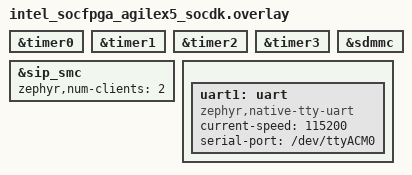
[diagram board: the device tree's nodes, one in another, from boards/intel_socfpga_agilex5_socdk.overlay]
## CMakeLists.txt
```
# SPDX-License-Identifier: Apache-2.0

cmake_minimum_required(VERSION 3.20.0)
find_package(Zephyr REQUIRED HINTS $ENV{ZEPHYR_BASE})
project(shell_module)

target_sources(app PRIVATE src/main.c mylib/test_module.c)
target_sources_ifdef(CONFIG_SHELL_DYNAMIC_CMDS app PRIVATE mylib/dynamic_cmd.c)
target_sources_ifdef(CONFIG_SHELL_BACKEND_SERIAL app PRIVATE mylib/uart_reinit.c)
target_sources_ifdef(CONFIG_SHELL_BACKEND_SERIAL app PRIVATE include/ahu_led.h)
target_sources_ifdef(CONFIG_SHELL_BACKEND_SERIAL app PRIVATE include/ahu_shell.h)
target_sources_ifdef(CONFIG_SHELL_BACKEND_SERIAL app PRIVATE include/ahu_timer.h)
target_sources_ifdef(CONFIG_SHELL_BACKEND_SERIAL app PRIVATE include/ahu_uart.h)
target_sources_ifdef(CONFIG_SHELL_BACKEND_SERIAL app PRIVATE include/hci.h)
target_sources_ifdef(CONFIG_SHELL_BACKEND_SERIAL app PRIVATE include/ble_central.h)
target_sources_ifdef(CONFIG_SHELL_BACKEND_SERIAL app PRIVATE include/ble_devices.h)
target_sources_ifdef(CONFIG_SHELL_BACKEND_SERIAL app PRIVATE include/ble_rules.h)
target_sources_ifdef(CONFIG_SHELL_BACKEND_SERIAL app PRIVATE ../Thingy52/include/ble_defs.h)
```

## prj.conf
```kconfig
CONFIG_PRINTK=y
CONFIG_SHELL=y
CONFIG_LOG=y
CONFIG_LOG_CMDS=y
CONFIG_INIT_STACKS=y
CONFIG_THREAD_STACK_INFO=y
CONFIG_KERNEL_SHELL=y
CONFIG_THREAD_MONITOR=y
CONFIG_BOOT_BANNER=n
CONFIG_THREAD_NAME=y
CONFIG_DEVICE_SHELL=y
CONFIG_POSIX_CLOCK=y
CONFIG_DATE_SHELL=y
CONFIG_THREAD_RUNTIME_STATS=y
CONFIG_THREAD_RUNTIME_STATS_USE_TIMING_FUNCTIONS=y
CONFIG_STATS=y
CONFIG_STATS_SHELL=y
CONFIG_SERIAL=y
CONFIG_UART_USE_RUNTIME_CONFIGURE=y
CONFIG_SERIAL=y
CONFIG_UART_INTERRUPT_DRIVEN=y
CONFIG_UART_1_INTERRUPT_DRIVEN=y
CONFIG_BT=y
CONFIG_LOG=y
CONFIG_BT_CENTRAL=y
CONFIG_BT_SMP=y
CONFIG_BT_GATT_CLIENT=y
CONFIG_DEBUG_OPTIMIZATIONS=y
CONFIG_COMPILER_OPT=""
CONFIG_PRINTK_BUFFER_SIZE=256
```

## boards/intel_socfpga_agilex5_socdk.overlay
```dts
/*
 * Copyright (C) 2023 Intel Corporation
 * SPDX-License-Identifier: Apache-2.0
 */

/*
 * The overlay file should be used to enable any
 * dts nodes required by this shell application for this
 * board.
 *
 * Nothing here as of now.
 */

&timer0 {
	status = "okay";
};

&timer1 {
	status = "okay";
};

&timer2 {
	status = "okay";
};

&timer3 {
	status = "okay";
};

&sip_smc {
	status = "okay";
	zephyr,num-clients = <2>;
};

&sdmmc {
	status = "okay";
};

{
uart1: uart {
	status = "okay";
	compatible = "zephyr,native-tty-uart";
	current-speed = <115200>;
	serial-port = "/dev/ttyACM0";
	};
};
```

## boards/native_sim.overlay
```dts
/ {
	uart0: uart {
		status = "okay";
		compatible = "zephyr,native-tty-uart";
		current-speed = <115200>;
		serial-port = "/dev/ttyUSB0";
	};

	uart1: uart1 {
		status = "okay";
		compatible = "zephyr,native-tty-uart";
		current-speed = <115200>;
		serial-port = "/dev/ttyUSB1";
	};
};
```

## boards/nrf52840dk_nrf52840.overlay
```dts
&pinctrl {
	uart1_default: uart1_default {
		group1 {
			psels = <NRF_PSEL(UART_TX, 1, 1)>;
		};
        group2 {
            psels = <NRF_PSEL(UART_RX, 1, 2)>;
        };

	};
	/* required if CONFIG_PM_DEVICE=y */
	uart1_sleep: uart1_sleep {
		group1 {
			psels = <NRF_PSEL(UART_TX, 1, 1)>,
					<NRF_PSEL(UART_RX, 1, 1)>;
			low-power-enable;
		};
	};
};

&uart1 {
	compatible = "nordic,nrf-uarte";
	current-speed = <115200>;
	status = "okay";
	pinctrl-0 = <&uart1_default>;
	pinctrl-1 = <&uart1_sleep>;
	pinctrl-names = "default", "sleep";
};
```

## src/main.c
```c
/*
 * File:   main.c
 * Author: Shreya Singh
 *
 * Created on March 2, 2024, 8:00AM
 * Description: AHU Driver Main 
 * 
 */

#include <zephyr/kernel.h>
#include <zephyr/shell/shell.h>
#include <version.h>
#include <zephyr/logging/log.h>
#include <stdlib.h>
#include <zephyr/drivers/uart.h>
#include <zephyr/usb/usb_device.h>
#include <ctype.h>
#include <math.h>
#include <inttypes.h>
#include <stdio.h>
#include <zephyr/drivers/gpio.h>
#include <zephyr/device.h>
#include <string.h>


#ifdef CONFIG_ARCH_POSIX
#include <unistd.h>
#else
#include <zephyr/posix/unistd.h>
#endif

//Library Files 
#include "../include/ahu_led.h"
#include "../include/ahu_shell.h"
#include "../include/ahu_timer.h"
#include "../include/ahu_uart.h"
#include "../include/hci.h"
#include <zephyr/sys/rb.h>
#include "../include/hci.h"
#include "../include/ble_devices.h"
#include "../include/ble_rules.h"
#include "../include/ble_central.h"


/* size of stack area used by each thread */
#define STACKSIZE 1024

/* scheduling priority used by each thread */
#define PRIORITY 7

//SHELL TEST FUNCTION 


// UART TEST FUNCTION
static int sendsend(const struct shell *sh, size_t argc, char **argv){ 
	ARG_UNUSED(argc);
	ARG_UNUSED(argv);
	send_str(uart1, "ITS WORKING\n");
	return 0;
}

SHELL_CMD_REGISTER(send, NULL, "Send UART", sendsend);

/**
 * @brief Initializes the functionality of the system.
 * 
 * This function initializes the AHU LED and system timer functionality.
 * 
 * @note Make sure to call this function before using any other system functionalities.
 */
void init(void){ 
	ahu_led_init(); 
	ahu_system_timer_init();
}

/* 
 * Initializes the system and enables shell functionality.
 * This function sets up necessary components and configurations
 * to start the system and activate the shell for user interaction.
 * It includes initialization of system components like LEDs, timers,
 * and other peripherals required for system operation.
 * 
 * Returns:
 * - 0 if initialization is successful.
 */
int shell(void)
{
	init(); 
	
#if DT_NODE_HAS_COMPAT(DT_CHOSEN(zephyr_shell_uart), zephyr_cdc_acm_uart)
	const struct device *dev;
	uint32_t dtr = 0;

	dev = DEVICE_DT_GET(DT_CHOSEN(zephyr_shell_uart));
	if (!device_is_ready(dev) || usb_enable(NULL)) {
		return 0;
	}
	while (!dtr) {
		uart_line_ctrl_get(dev, UART_LINE_CTRL_DTR, &dtr);
		k_sleep(K_MSEC(100));
		

	}
#endif
	return 0;
}

// // Initialise Message Queues
// K_MSGQ_DEFINE(my_msgq, sizeof(struct data_item_type), 10, 1); // BLE msg queue
// // K_MSGQ_DEFINE(my_uartmsgq, sizeof(struct uart_item_type), 10, 1); // UART msg queue

// // // Initialise Threads 
K_THREAD_DEFINE(shell_id, STACKSIZE, shell, NULL, NULL, NULL,
			2, 0, 0); // Shell Thread 

K_THREAD_DEFINE(ble_id, STACKSIZE, ble, NULL, NULL, NULL,
7, 0, 0); // Bluetooth Thread 

// K_THREAD_DEFINE(message_update_id, STACKSIZE, send, NULL, NULL, NULL,
// 1, 0, 0); // BLE update message 

// K_THREAD_DEFINE(HCI_poll_id, STACKSIZE, hci_data_packet_poll, NULL, NULL, NULL,
// 9, 0, 0); // UART poll thread 

// K_THREAD_DEFINE(uart_id, STACKSIZE, uart_update, NULL, NULL, NULL,
// 7, 0, 0);// Update UART message thread 
```

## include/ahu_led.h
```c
/*
 * File:   ahu_led.h
 * Author: Shreya Singh
 *
 * Created on March 2, 2023, 8:00 AM
 * Description: This header file contains declarations for functions and
 *              data structures used in the ahu_led.c.
 * 
 */
#ifndef AHU_LED_H
#define AHU_LED_H

#include <ctype.h>
#include <math.h>
#include <inttypes.h>
#include <stdio.h>
#include <zephyr/drivers/gpio.h>
#include "../mylib/ahu_led.c"


void ahu_led_init(void);
void set_ahu_led(int led, const char *status); 
int get_ahu_led_status(int led);
void toggle_ahu_led(int led); 

#endif /* AHU_LED_H*/
```

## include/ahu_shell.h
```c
/*
 * File:   ahu_shell.h
 * Author: Shreya Singh
 *
 * Created on March 2, 2023, 8:00 AM
 * Description: This header file contains declarations for functions and
 *              data structures used in the ahu_shell.c.
 * 
 */

#ifndef AHU_SHELL_H
#define AHU_SHELL_H
#include "../mylib/ahu_shell.c"

static int cmd_time_null(const struct shell *sh, size_t argc, char **argv);
static int cmd_time_f(const struct shell *sh, size_t argc, char **argv);
static int cmd_led_s(const struct shell *sh, size_t argc, char **argv);
static int cmd_led_tog(const struct shell *sh, size_t argc, char **argv);
static int cmd_circle_rxy(const struct shell *sh, size_t argc, char **argv);
static int cmd_point_xy(const struct shell *sh, size_t argc, char **argv);
static int cmd_gpd(const struct shell *sh, size_t argc, char **argv);
static int cmd_gled_rgb(const struct shell *sh, size_t argc, char **argv);
static int cmd_dac_xy(const struct shell *sh, size_t argc, char **argv);
static int cmd_lj_abt(const struct shell *sh, size_t argc, char **argv);
static int cmd_blescan_s(const struct shell *sh, size_t argc, char **argv);
static int cmd_blescan_p(const struct shell *sh, size_t argc, char **argv);
static int cmd_blecon_s(const struct shell *sh, size_t argc, char **argv);
static int cmd_blecon_p(const struct shell *sh, size_t argc, char **argv);
static int cmd_gcugraph(const struct shell *sh, size_t argc, char **argv);
static int cmd_gcumeter(const struct shell *sh, size_t argc, char **argv);
static int cmd_gcunumeric(const struct shell *sh, size_t argc, char **argv);
static int cmd_gcurec_s(const struct shell *sh, size_t argc, char **argv);
static int cmd_gcurec_p(const struct shell *sh, size_t argc, char **argv);
void blink(void); 
static int cmd_view_device(const struct shell *sh, size_t argc, char **argv);
static int cmd_viewall_device(const struct shell *sh, size_t argc, char **argv);
static int cmd_add_device(const struct shell *sh, size_t argc, char **argv);
static int cmd_remove_device(const struct shell *sh, size_t argc, char **argv);

//SHELL NODE DEFINITIONS
SHELL_STATIC_SUBCMD_SET_CREATE(sub_viewdevice,
	SHELL_CMD(-a, NULL, "View Device", cmd_view_device),

	SHELL_SUBCMD_SET_END /* Array terminated. */
);
SHELL_CMD_REGISTER(view, &sub_viewdevice, "Device Commands",cmd_viewall_device);


SHELL_CMD_REGISTER(add, NULL, "Add Device", cmd_add_device);
SHELL_CMD_REGISTER(remove, NULL, "Remove Device", cmd_remove_device);


SHELL_STATIC_SUBCMD_SET_CREATE(sub_time,
	SHELL_CMD(f, NULL, "Format -H -M -S", cmd_time_f),
	SHELL_SUBCMD_SET_END /* Array terminated. */
);
SHELL_CMD_REGISTER(time, &sub_time, "Time Commands", cmd_time_null);



SHELL_STATIC_SUBCMD_SET_CREATE(sub_led,
	SHELL_CMD(s, NULL, "Set LEDs", cmd_led_s),
	SHELL_CMD(t, NULL, "Toggle LEDs", cmd_led_tog),
	SHELL_SUBCMD_SET_END /* Array terminated. */
);
SHELL_CMD_REGISTER(led, &sub_led, "LED Commands",NULL);


SHELL_STATIC_SUBCMD_SET_CREATE(sub_blescan,
	SHELL_CMD(-s, NULL, "Start Scanning", cmd_blescan_s),
	SHELL_CMD(-p, NULL, "Stop Scanning", cmd_blescan_p),
	SHELL_SUBCMD_SET_END /* Array terminated. */
);
SHELL_CMD_REGISTER(blescan, &sub_blescan, "BLE Scan Commands",NULL);

SHELL_STATIC_SUBCMD_SET_CREATE(sub_blecon,
	SHELL_CMD(-s, NULL, "Start Scanning", cmd_blecon_s),
	SHELL_CMD(-p, NULL, "Stop Scanning", cmd_blecon_p),
	SHELL_SUBCMD_SET_END /* Array terminated. */
);
SHELL_CMD_REGISTER(blecon, &sub_blecon, "BLE Sensor Commands",NULL);

SHELL_STATIC_SUBCMD_SET_CREATE(sub_gcurec,
	SHELL_CMD(-s, NULL, "Start Recording Sensor", cmd_gcurec_s),
	SHELL_CMD(-p, NULL, "Stop Recording Sensor", cmd_gcurec_p),
	SHELL_SUBCMD_SET_END /* Array terminated. */
);
SHELL_CMD_REGISTER(gcurec, &sub_gcurec, "BLE Record Sensors",NULL);


SHELL_CMD_REGISTER(point, NULL, "Draw a point - point x y", cmd_point_xy);
SHELL_CMD_REGISTER(circle, NULL, "Draw a circle - circle r, x, y", cmd_circle_rxy);
SHELL_CMD_REGISTER(gpd, NULL, "GCU Pushbutton status", cmd_gpd);
SHELL_CMD_REGISTER(gled, NULL, "Toggle GCU LEDs - gled r g b", cmd_gled_rgb);
SHELL_CMD_REGISTER(dac, NULL, "Set DAC values - dac x y",cmd_dac_xy);
SHELL_CMD_REGISTER(lj, NULL, "Set the a and b parameters for the Lissajous curve",cmd_lj_abt);
SHELL_CMD_REGISTER(gcugraph, NULL, "Send sensor value to GCU Graph",cmd_gcugraph);
SHELL_CMD_REGISTER(gcumeter, NULL, "Send sensor value to GCU Meter",cmd_gcumeter);
SHELL_CMD_REGISTER(gcunumeric, NULL, "Send sensor value to GCU DAC",cmd_gcunumeric);

#endif /* AHU_SHELL_H*/
```

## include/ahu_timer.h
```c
/*
 * File:   ahu_timer.h
 * Author: Shreya Singh
 *
 * Created on March 2, 2023, 8:00 AM
 * Description: This header file contains declarations for functions and
 *              data structures used in the ahu_timer.c.
 * 
 */

#ifndef AHU_TIMER_H
#define AHU_TIMER_H
#include "../mylib/ahu_timer.c"

void ahu_system_timer_init(); 
int get_system_time_null();
int* get_system_time_f();


#endif /* AHU_TIMER_H*/
```

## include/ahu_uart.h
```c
/*
 * File:   ahu_uart.h
 * Author: Shreya Singh
 *
 * Created on March 2, 2023, 8:00 AM
 * Description: This header file contains declarations for functions and
 *              data structures used in the ahu_uart.c.
 * 
 */

#ifndef AHU_UART_H
#define AHU_UART_H
#include "../mylib/ahu_uart.c"
//UART NODE DEFINITION
const struct device *uart1 = DEVICE_DT_GET(DT_NODELABEL(uart1));

struct uart_config uart_cfg = {
	.baudrate = 115200,
	.parity = UART_CFG_PARITY_NONE,
	.stop_bits = UART_CFG_STOP_BITS_1,
	.flow_ctrl = UART_CFG_FLOW_CTRL_NONE,
	.data_bits = UART_CFG_DATA_BITS_8,
};

void send_str(const struct device *uart, char *str);
void recv_str(const struct device *uart, char *str);
extern char file[20]; 


#endif /* AHU_UART_H*/
```

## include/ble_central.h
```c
/*
 * File:   ble_central.h
 * Author: Shreya Singh
 *
 * Created on March 19, 2023, 8:00 AM
 * Description: This header file contains declarations for functions and
 *              data structures used in the ble_central.c.
 * 
 */

#ifndef BLE_CENTRAL_H
#define BLE_CENTRAL_H
#include <zephyr/types.h>
#include <stddef.h>
#include <errno.h>
#include <zephyr/kernel.h>
#include <zephyr/sys/printk.h>

#include <zephyr/bluetooth/bluetooth.h>
#include <zephyr/bluetooth/hci.h>
#include <zephyr/bluetooth/conn.h>
#include <zephyr/bluetooth/uuid.h>
#include <zephyr/bluetooth/gatt.h>
#include <zephyr/sys/byteorder.h>

#include "../mylib/ble_central.c"


static void start_scan(void);
int ble(void); 
void send(void);

#endif /* BLE_CENTRAL_H*/
```

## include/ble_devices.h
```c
/*
 * File:   ble_devices.h
 * Author: Shreya Singh
 *
 * Created on March 19, 2023, 8:00 AM
 * Description: This header file contains declarations for functions and
 *              data structures used in the BLE
 * 
 */

#ifndef BLE_DEVICES_H
#define BLE_DEVICES_H
#include <zephyr/types.h>
#include <stddef.h>
#include <errno.h>
#include <zephyr/kernel.h>
#include <zephyr/sys/printk.h>

#include <zephyr/bluetooth/bluetooth.h>
#include <zephyr/bluetooth/hci.h>
#include <zephyr/bluetooth/conn.h>
#include <zephyr/bluetooth/uuid.h>
#include <zephyr/bluetooth/gatt.h>
#include <zephyr/sys/byteorder.h>


#include <zephyr/sys/util.h>
#include <zephyr/sys/slist.h>
#include <zephyr/sys/rb.h>
#include <stdio.h>
#include "../mylib/ble_devices.c"


void remove_node_by_name(const char *name);
void add_node(char *name, uint16_t mac_address, uint16_t major, uint16_t minor,
              uint16_t x_coord, uint16_t y_coord, uint16_t left_nb, uint16_t right_nb);
void view_node_by_name(char *name);
void view_all_nodes(void);

#endif /* BLE_DEVICES_H*/
```

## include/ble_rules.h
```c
/*
 * File:   ble_devices.h
 * Author: Shreya Singh
 *
 * Created on March 19, 2023, 8:00 AM
 * Description: This header file contains declarations for functions and
 *              data structures used in the BLE
 * 
 */

#ifndef BLE_RULES_H
#define BLE_RULES_H
#include <zephyr/types.h>
#include <stddef.h>
#include <errno.h>
#include <zephyr/kernel.h>
#include <zephyr/sys/printk.h>
#include <zephyr/bluetooth/bluetooth.h>
#include <zephyr/bluetooth/hci.h>
#include <zephyr/bluetooth/conn.h>
#include <zephyr/bluetooth/uuid.h>
#include <zephyr/bluetooth/gatt.h>
#include <zephyr/sys/byteorder.h>
#include <zephyr/sys/util.h>
#include <zephyr/sys/slist.h>
#include <zephyr/sys/rb.h>
#include <stdio.h>
#include "../../Thingy52/include/ble_defs.h"
#define MAX_DEVICES 12
#define UUID_LENGTH 6

// Define the struct for iBeacon node
struct ibeacon_node {
    char ble_name[32]; // BLE Name
    char ble_mac_address[18]; // BLE MAC address
    uint16_t ble_major_number; // BLE major number
    uint16_t ble_minor_number; // BLE minor number
    int16_t x_coordinate; // Fixed X coordinate
    int16_t y_coordinate; // Fixed Y coordinate
    int16_t left_neighbor; // hex position [x,y]
    int16_t right_neighbor; // hex position [x,y]
};
// Define the struct for iBeacon node
struct ibeacon_node2 {
    char ble_name[32]; // BLE Name
    uint16_t ble_mac_address; // BLE MAC address
    uint16_t ble_major_number; // BLE major number
    uint16_t ble_minor_number; // BLE minor number
    int16_t x_coordinate; // Fixed X coordinate
    int16_t y_coordinate; // Fixed Y coordinate
    int16_t left_neighbor; // hex position [x,y]
    int16_t right_neighbor; // hex position [x,y]
};

int num_nodes = 8; 

struct ibeacon_node nodes[MAX_DEVICES] = {
    [0] = {
        .ble_name = "4011-A",
        .ble_mac_address = "F5:75:FE:85:34:67",
        .ble_major_number = 2753,
        .ble_minor_number = 32998,
        .x_coordinate = 0,
        .y_coordinate = 0,
        .left_neighbor = 0x02,
        .right_neighbor = 0x20,
    },
    [1] = {
        .ble_name = "4011-B",
        .ble_mac_address = "E5:73:87:06:1E:86",
        .ble_major_number = 32975,
        .ble_minor_number = 20959,
        .x_coordinate = 2,
        .y_coordinate = 0,
        .left_neighbor = 0x00,
        .right_neighbor = 0x40,
    },
    [2] = {
        .ble_name = "4011-C",
        .ble_mac_address = "CA:99:9E:FD:98:B1",
        .ble_major_number = 26679,
        .ble_minor_number = 40363,
        .x_coordinate = 4,
        .y_coordinate = 0,
        .left_neighbor = 0x20,
        .right_neighbor = 0x42,
    },
    [3] = {
        .ble_name = "4011-D",
        .ble_mac_address = "CB:1B:89:82:FF:FE",
        .ble_major_number = 41747,
        .ble_minor_number = 38800,
        .x_coordinate = 4,
        .y_coordinate = 2,
        .left_neighbor = 0x44,
        .right_neighbor = 0x40,
    },
    [4] = {
        .ble_name = "4011-E",
        .ble_mac_address = "D4:D2:A0:A4:5C:AC",
        .ble_major_number = 30679,
        .ble_minor_number = 51963,
        .x_coordinate = 4,
        .y_coordinate = 4,
        .left_neighbor = 0x42,
        .right_neighbor = 0x24,
    },
    [5] = {
        .ble_name = "4011-F",
        .ble_mac_address = "C1:13:27:E9:B7:7C",
        .ble_major_number = 6195,
        .ble_minor_number = 18394,
        .x_coordinate = 2,
        .y_coordinate = 4,
        .left_neighbor = 0x44,
        .right_neighbor = 0x04,
    },
    [6] = {
        .ble_name = "4011-G",
        .ble_mac_address = "F1:04:48:06:39:A0",
        .ble_major_number = 30525,
        .ble_minor_number = 30544,
        .x_coordinate = 0,
        .y_coordinate = 4,
        .left_neighbor = 0x24,
        .right_neighbor = 0x02,
    },
    [7] = {
        .ble_name = "4011-H",
        .ble_mac_address = "CA:0C:E0:DB:CE:60",
        .ble_major_number = 57395,
        .ble_minor_number = 28931,
        .x_coordinate = 0,
        .y_coordinate = 2,
        .left_neighbor = 0x04,
        .right_neighbor = 0x00,
    },

};

struct ibeacon_node2 nodes2[MAX_DEVICES] = {
    [0] = {
        .ble_name = "4011-A",
        .ble_mac_address = 0x75,
        .ble_major_number = 2753,
        .ble_minor_number = 32998,
        .x_coordinate = 0,
        .y_coordinate = 0,
        .left_neighbor = 0x02,
        .right_neighbor = 0x20,
    },
    [1] = {
        .ble_name = "4011-B",
        .ble_mac_address = 0x73,
        .ble_major_number = 32975,
        .ble_minor_number = 20959,
        .x_coordinate = 2,
        .y_coordinate = 0,
        .left_neighbor = 0x00,
        .right_neighbor = 0x40,
    },
    [2] = {
        .ble_name = "4011-C",
        .ble_mac_address = 0x99,
        .ble_major_number = 26679,
        .ble_minor_number = 40363,
        .x_coordinate = 4,
        .y_coordinate = 0,
        .left_neighbor = 0x20,
        .right_neighbor = 0x42,
    },
    [3] = {
        .ble_name = "4011-D",
        .ble_mac_address = 0x1B,
        .ble_major_number = 41747,
        .ble_minor_number = 38800,
        .x_coordinate = 4,
        .y_coordinate = 2,
        .left_neighbor = 0x44,
        .right_neighbor = 0x40,
    },
    [4] = {
        .ble_name = "4011-E",
        .ble_mac_address = 0xD2,
        .ble_major_number = 30679,
        .ble_minor_number = 51963,
        .x_coordinate = 4,
        .y_coordinate = 4,
        .left_neighbor = 0x42,
        .right_neighbor = 0x24,
    },
    [5] = {
        .ble_name = "4011-F",
        .ble_mac_address = 0x13,
        .ble_major_number = 6195,
        .ble_minor_number = 18394,
        .x_coordinate = 2,
        .y_coordinate = 4,
        .left_neighbor = 0x44,
        .right_neighbor = 0x04,
    },
    [6] = {
        .ble_name = "4011-G",
        .ble_mac_address = 0x04,
        .ble_major_number = 30525,
        .ble_minor_number = 30544,
        .x_coordinate = 0,
        .y_coordinate = 4,
        .left_neighbor = 0x24,
        .right_neighbor = 0x02,
    },
    [7] = {
        .ble_name = "4011-H",
        .ble_mac_address = 0x0C,
        .ble_major_number = 57395,
        .ble_minor_number = 28931,
        .x_coordinate = 0,
        .y_coordinate = 2,
        .left_neighbor = 0x04,
        .right_neighbor = 0x00,
    },
    // [8] = {
    //     .ble_name = "4011-I",
    //     .ble_mac_address = 0xFF,
    //     .ble_major_number = 2753,
    //     .ble_minor_number = 32998,
    //     .x_coordinate = 2,
    //     .y_coordinate = 4,
    //     .left_neighbor = 0x02,
    //     .right_neighbor = 0x20,
    // },

};

// Struct of Devices 
static uint8_t UUID_data[] ={DISCRIMINATOR, 0x00, /* Apple */
    0x02, 0x15, /* iBeacon */
    UUID_SHREYANODE,UUID_SHREYANODE_NUM, // UUID for IBEACON MOBILE
    0x00, 0x00, //ADDR1_1, ADDR1_2, 
    0x00, 0x00, //ADDR1_3, ADDR1_4,
    0x00, 0x00, //ADDR1_5, ADDR1_6,
    0x00, UUID_SHREYANODE, //ADDR1_RSSI, UUID_SHREYANODE, 
    0x00, 0x00,//ADDR2_1, ADDR2_2,s
    0x00, 0x00, //ADDR2_3, ADDR2_4, 
    0x00, 0x00, //ADDR2_5, ADDR2_6, 
    0x00, UUID_SHREYANODE, //ADDR2_RSSI, UUID_SHREYANODE, 
    0x00, 0x00, //0x00, PACKET_NUM, 
    UUID_SHREYANODE_NUM, // END of transmission
};

    // [8] = {
    //     .ble_name = "4011-I",
    //     .ble_mac_address = "00:00:00:00:00:00",
    //     .ble_major_number = 2753,
    //     .ble_minor_number = 32998,
    //     .x_coordinate = 3,
    //     .y_coordinate = 4,
    //     .left_neighbor = 0x02,
    //     .right_neighbor = 0x20,
    // },
#endif /* BLE_RULES_H*/
```

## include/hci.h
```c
/*
 * File:   hci.h
 * Author: Shreya Singh
 *
 * Created on March 2, 2023, 8:00 AM
 * Description: This header file contains declarations for functions and
 *              data structures used in the hci.c.
 * 
 */

#ifndef HCI_H
#define HCI_H
#include <zephyr/types.h>
#include <stddef.h>
#include <errno.h>
#include <zephyr/kernel.h>
#include <zephyr/sys/printk.h>
#include "../mylib/hci.c"

// Preamble Definition
#define PREAMBLE 0xAA

// Type Definition
#define REQUEST 0x2
#define RESPONSE 0x1

// Device ID
#define GCU_LED 0x1
#define GCU_BUTTON 0x2
#define GCU_DAC 0x3
#define GCU_LJ 0x4
#define TEMP 0x5
#define HUMID 0x6
#define AP 0x7
#define TVOC 0x8
#define SD 13

// Cmd Definition
#define cmd_point 'p'
#define cmd_circle 'c'
#define cmd_lissajous 'j'
#define cmd_dac 'd'
#define cmd_led 'l'
#define cmd_button 'b'
#define gcugraph_cmd 'g'
#define gcumeter_cmd 'm'
#define gcunumeric_cmd 'n'
#define gcurec_cmd 'r'

// Function Definition
void hci_data_packet_poll();
void blink(); 

#endif /* HCI_H*/
```
